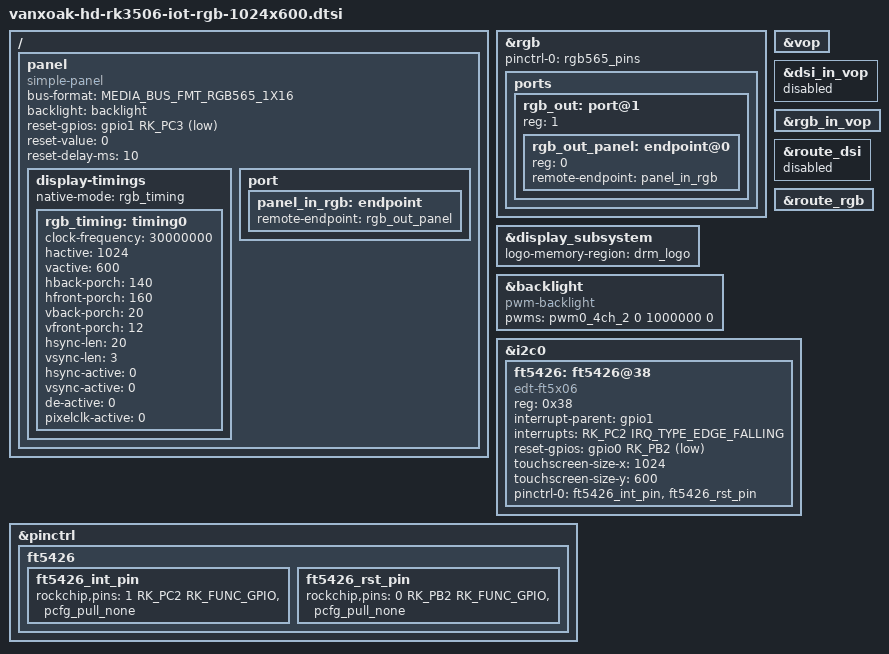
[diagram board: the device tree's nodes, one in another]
#include <dt-bindings/display/media-bus-format.h>

/ {
	panel: panel {
		compatible = "simple-panel";
		bus-format = <MEDIA_BUS_FMT_RGB565_1X16>;
		backlight = <&backlight>;
		//enable-gpios = <&gpio1 RK_PA0 GPIO_ACTIVE_HIGH>;
		//enable-delay-ms = <20>;
		reset-gpios = <&gpio1 RK_PC3 GPIO_ACTIVE_LOW>;
		reset-value = <0>;
		reset-delay-ms = <10>;
		status = "okay";

		display-timings {
			native-mode = <&rgb_timing>;

			rgb_timing: timing0 {
				clock-frequency = <30000000>;
				hactive = <1024>;
				vactive = <600>;
				hback-porch = <140>;
				hfront-porch = <160>;
				vback-porch = <20>;
				vfront-porch = <12>;
				hsync-len = <20>;
				vsync-len = <3>;
				hsync-active = <0>;
				vsync-active = <0>;
				de-active = <0>;
				pixelclk-active = <0>;
			};
		};

		port {
			panel_in_rgb: endpoint {
				remote-endpoint = <&rgb_out_panel>;
			};
		};
	};

};

&rgb {
	status = "okay";
	pinctrl-names = "default";
	pinctrl-0 = <&rgb565_pins>;

	ports {
		rgb_out: port@1 {
			reg = <1>;
			#address-cells = <1>;
			#size-cells = <0>;

			rgb_out_panel: endpoint@0 {
				reg = <0>;
				remote-endpoint = <&panel_in_rgb>;
			};
		};
	};
};

&display_subsystem {
	status = "okay";
	logo-memory-region = <&drm_logo>;
};

&vop {
	status = "okay";
};

&dsi_in_vop {
	status = "disabled";
};

&rgb_in_vop {
	status = "okay";
};

&route_dsi {
	status = "disabled";
};

&route_rgb {
	status = "okay";
};

&backlight {
	compatible = "pwm-backlight";
	pwms = <&pwm0_4ch_2 0 1000000 0>;
	status = "okay";
};

// TOUCH
&i2c0 {
	status = "okay";

	ft5426: ft5426@38 {
        compatible = "edt-ft5x06","edt,edt-ft5406";
        reg = <0x38>;
        interrupt-parent = <&gpio1>;
        interrupts = <RK_PC2 IRQ_TYPE_EDGE_FALLING>;

        reset-gpios = <&gpio0 RK_PB2 GPIO_ACTIVE_LOW>;

        touchscreen-size-x = <1024>;
        touchscreen-size-y = <600>;

        pinctrl-names = "default";
        pinctrl-0 = <&ft5426_int_pin &ft5426_rst_pin>;

        status = "okay";
	};

};

&pinctrl {
	ft5426{
		ft5426_int_pin: ft5426_int_pin {
			rockchip,pins = <1 RK_PC2 RK_FUNC_GPIO &pcfg_pull_none>;
		};
		ft5426_rst_pin: ft5426_rst_pin {
			rockchip,pins = <0 RK_PB2 RK_FUNC_GPIO &pcfg_pull_none>;
		};
	};
};





